# H6 register map
Vendor: Allwinner; Series: H6; File version: 0.1
CPU: CA53 0, little endian, MPU, no FPU, 0 interrupt priority bits
Registers are 32-bit, read-write, reset 0x0 unless marked. A register's access mark holds for its fields unless they carry their own. Offsets are from the block's base; [hi:lo] are bit positions; lines under a group give offsets from that group; {n}, {i} and the like mark numbered series.

## MSGBOX
Base 0x03003000
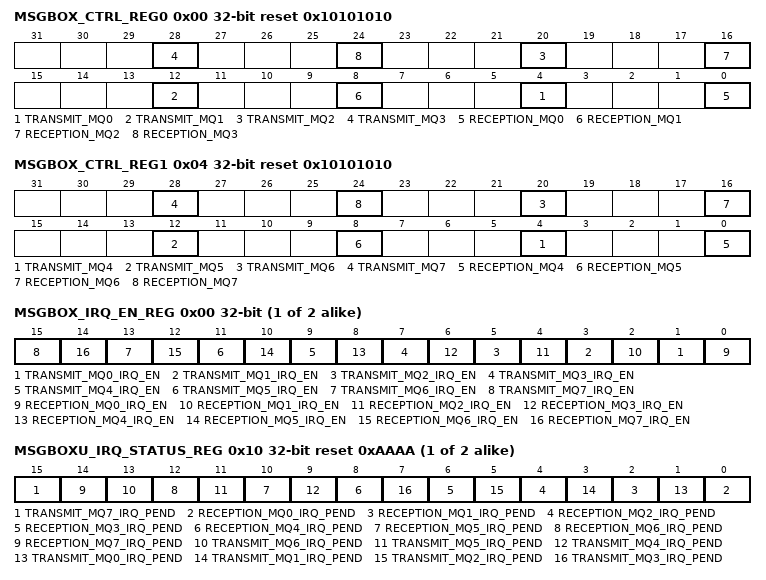
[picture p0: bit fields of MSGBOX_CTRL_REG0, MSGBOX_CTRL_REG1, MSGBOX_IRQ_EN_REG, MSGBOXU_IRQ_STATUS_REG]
0x00 MSGBOX_CTRL_REG0 reset 0x10101010 — Message Queue Attribute Control Register 0
  [all] fields
    0=user0; 1=user1
  [8n+4] TRANSMIT_MQ{n} (n=0..3) — Message Queue {n} is a Transmitter of user u. 0: user0 1: user1
  [8n] RECEPTION_MQ{n} (n=0..3) — Message Queue {n} is a Receiver of user u. 0: user0 1: user1
0x04 MSGBOX_CTRL_REG1 reset 0x10101010 — Message Queue Attribute Control Register 1
  [all] fields
    0=user0; 1=user1
  [8n-28] TRANSMIT_MQ{n} (n=4..7) — Message Queue {n} is a Transmitter of user u. 0: user0 1: user1
  [8n-32] RECEPTION_MQ{n} (n=4..7) — Message Queue {n} is a Receiver of user u. 0: user0 1: user1
{0x40+0x20*i} _N[{i}] (i=0..1) group
  0x00 MSGBOX_IRQ_EN_REG
    [2n+1] TRANSMIT_MQ{n}_IRQ_EN (n=0..7) — 0: Disable 1: Enable (It will notify user u by interrupt when Message Queue {n} is not full.)
      0=Disable; 1=Enable (It will notify user u by interrupt when Message Queue {n} is not full.)
    [2n] RECEPTION_MQ{n}_IRQ_EN (n=0..7) — 0: Disable 1: Enable (It will notify user u by interrupt when Message Queue {n} has received a new message.)
      0=Disable; 1=Enable (It will notify user u by interrupt when Message Queue {n} has received a new message.)
  0x10 MSGBOXU_IRQ_STATUS_REG reset 0xAAAA — IRQ Status for User n ( n=0,1)
    [15] TRANSMIT_MQ7_IRQ_PEND — 0: No effect 1: Pending. This bit will be pending for user u when Message Queue 7 is not full. Setting one to this bit will clear it.
      0=No_effect; 1=Pending. This bit will be pending for user u when Message Queue 7 is not full. Setting one to this bit will clear it.
    [2n] RECEPTION_MQ{n}_IRQ_PEND (n=0..7) — 0: No effect 1: Pending. This bit will be pending for user u when Message Queue {n} has received a new message. Setting one to this bit will clear it.
      0=No_effect; 1=Pending. This bit will be pending for user u when Message Queue {n} has received a new message. Setting one to this bit will clear it.
    [13] TRANSMIT_MQ6_IRQ_PEND — 0: No effect 1: Pending. This bit will be pending for user u when Message Queue 6 is not full. Setting one to this bit will clear it.
      0=No_effect; 1=Pending. This bit will be pending for user u when Message Queue 6 is not full. Setting one to this bit will clear it.
    [11] TRANSMIT_MQ5_IRQ_PEND — 0: No effect 1: Pending. This bit will be pending for user u when Message Queue 5 is not full. Setting one to this bit will clear it.
      0=No_effect; 1=Pending. This bit will be pending for user u when Message Queue 5 is not full. Setting one to this bit will clear it.
    [9] TRANSMIT_MQ4_IRQ_PEND — 0: No effect 1: Pending. This bit will be pending for user u when Message Queue 4 is not full. Set one to this bit will clear it.
      0=No_effect; 1=Pending. This bit will be pending for user u when Message Queue 4 is not full. Set one to this bit will clear it.
    [2n+1] TRANSMIT_MQ{n}_IRQ_PEND (n=0..3) — 0: No effect 1: Pending. This bit will be pending for user u when Message Queue {n} is not full. Setting one to this bit will clear it.
      0=No_effect; 1=Pending. This bit will be pending for user u when Message Queue {n} is not full. Setting one to this bit will clear it.
{0x100+4i} _N[{i}] (i=0..7) group
  0x00 MSGBOXM_FIFO_STATUS_REG — FIFO Status for Message Queue N(N = 0~7)
    [0] FIFO_FULL_FLAG ro — 0: The Message FIFO queue is not full (space is available) 1: The Message FIFO queue is full. This FIFO status register has the status related to the message queue.
      0=not_full (The Message FIFO queue is not full (space is available)); 1=full (The Message FIFO queue is full. This FIFO status register has the status related to the message queue.)
  0x40 MSGBOXM_MSG_STATUS_REG — Message Status for Message Queue N(N=0~7)
    [2:0] MSG_NUM ro — Number of unread messages in the message queue. Here, limited to four messages per message queue. 000: There is no message in the message FIFO queue. 001: There is 1 message in the message FIFO queue. 010: There are 2 messages in the message FIFO queue. 011: There are 3 messages in the message FIFO queue. 100: There are 4 messages in the message FIFO queue. 101~111:/
      0=no_message (There is no message in the message FIFO queue.); 1=There is 1 message in the message FIFO queue; 2=There are 2 messages in the message FIFO queue; 3=There are 3 messages in the message FIFO queue; 4=There are 4 messages in the message FIFO queue. 101~111:/
  0x80 MSGBOXM_MSG_REG — Message Register for Message Queue N(N=0~7)
    [31:0] MESSAGE — The message register stores the next to be read message of the message FIFO queue. Reads remove the message from the FIFO queue.
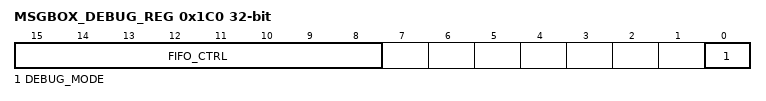
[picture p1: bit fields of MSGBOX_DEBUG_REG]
0x1C0 MSGBOX_DEBUG_REG — MSGBOX Debug Register
  [15:8] FIFO_CTRL — MQ[7:0] Control. In the debug mode, the corresponding FIFO channel will disable and only one register space valid for a message exchange. 0: Normal Mode. 1: Disable the corresponding FIFO (Clear FIFO).
  [0] DEBUG_MODE — In the Debug Mode, each user can transmit messages to itself through each Message Queue. 0: Normal Mode 1: Debug Mode.
    0=Normal Mode; 1=Debug Mode
